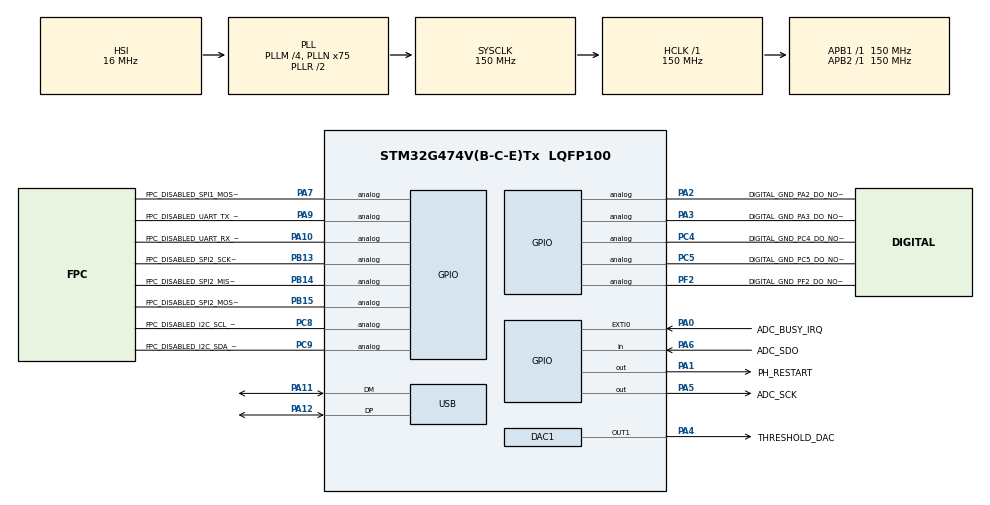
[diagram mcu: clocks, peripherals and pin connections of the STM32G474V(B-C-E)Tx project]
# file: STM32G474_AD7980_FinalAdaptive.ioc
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Mcu.Family=STM32G4
Mcu.Name=STM32G474V(B-C-E)Tx
Mcu.Package=LQFP100
NVIC.EXTI0_IRQn=true\:5\:0\:false\:false\:true\:true\:true\:true
NVIC.PriorityGroup=NVIC_PRIORITYGROUP_4
NVIC.USB_LP_IRQn=true\:6\:0\:true\:false\:true\:false\:true\:true
PA0.GPIO_Label=ADC_BUSY_IRQ
PA0.GPIO_ModeDefaultEXTI=GPIO_MODE_IT_FALLING
PA0.GPIO_PuPd=GPIO_NOPULL
PA0.Signal=GPXTI0
PA1.GPIO_Label=PH_RESTART
PA1.GPIO_PuPd=GPIO_NOPULL
PA1.GPIO_Speed=GPIO_SPEED_FREQ_HIGH
PA1.PinState=GPIO_PIN_RESET
PA1.Signal=GPIO_Output
PA2.GPIO_Label=DIGITAL_GND_PA2_DO_NOT_DRIVE
PA2.Signal=GPIO_Analog
PA3.GPIO_Label=DIGITAL_GND_PA3_DO_NOT_DRIVE
PA3.Signal=GPIO_Analog
PA11.Mode=Device
PA11.Signal=USB_DM
PA12.Mode=Device
PA12.Signal=USB_DP
PA4.GPIO_Label=THRESHOLD_DAC
PA4.Signal=COMP_DAC11_group
PA5.GPIO_Label=ADC_SCK
PA5.GPIO_PuPd=GPIO_NOPULL
PA5.GPIO_Speed=GPIO_SPEED_FREQ_VERY_HIGH
PA5.PinState=GPIO_PIN_RESET
PA5.Signal=GPIO_Output
PA6.GPIO_Label=ADC_SDO
PA6.GPIO_PuPd=GPIO_NOPULL
PA6.Signal=GPIO_Input
PA7.GPIO_Label=FPC_DISABLED_SPI1_MOSI_PA7
PA7.Signal=GPIO_Analog
PA9.GPIO_Label=FPC_DISABLED_UART_TX_PA9
PA9.Signal=GPIO_Analog
PA10.GPIO_Label=FPC_DISABLED_UART_RX_PA10
PA10.Signal=GPIO_Analog
PB13.GPIO_Label=FPC_DISABLED_SPI2_SCK_PB13
PB13.Signal=GPIO_Analog
PB14.GPIO_Label=FPC_DISABLED_SPI2_MISO_PB14
PB14.Signal=GPIO_Analog
PB15.GPIO_Label=FPC_DISABLED_SPI2_MOSI_PB15
PB15.Signal=GPIO_Analog
PC4.GPIO_Label=DIGITAL_GND_PC4_DO_NOT_DRIVE
PC4.Signal=GPIO_Analog
PC5.GPIO_Label=DIGITAL_GND_PC5_DO_NOT_DRIVE
PC5.Signal=GPIO_Analog
PC8.GPIO_Label=FPC_DISABLED_I2C_SCL_PC8
PC8.Signal=GPIO_Analog
PC9.GPIO_Label=FPC_DISABLED_I2C_SDA_PC9
PC9.Signal=GPIO_Analog
PF2.GPIO_Label=DIGITAL_GND_PF2_DO_NOT_DRIVE
PF2.Signal=GPIO_Analog
ProjectManager.HeapSize=0x800
ProjectManager.StackSize=0x1000
ProjectManager.TargetToolchain=STM32CubeIDE
RCC.ADC12Freq_Value=150000000
RCC.ADC345Freq_Value=150000000
RCC.AHBFreq_Value=150000000
RCC.APB1Freq_Value=150000000
RCC.APB1TimFreq_Value=150000000
RCC.APB2Freq_Value=150000000
RCC.APB2TimFreq_Value=150000000
RCC.CK48CLockSelection=RCC_USBCLKSOURCE_HSI48
RCC.CortexFreq_Value=150000000
RCC.EXTERNAL_CLOCK_VALUE=8000000
RCC.HCLKFreq_Value=150000000
RCC.HSE_VALUE=8000000
RCC.HSI48_VALUE=48000000
RCC.HSI_VALUE=16000000
RCC.LSE_VALUE=32768
RCC.PLLM=RCC_PLLM_DIV4
RCC.PLLN=75
RCC.SYSCLKFreq_VALUE=150000000
RCC.SYSCLKSource=RCC_SYSCLKSOURCE_PLLCLK
RCC.USBFreq_Value=48000000
RCC.VCOOutputFreq_Value=300000000
SH.COMP_DAC11_group.0=DAC1_OUT1,DAC_OUT1
USB.DeviceSpeed=PCD_SPEED_FULL
USB.Sof_enable=DISABLE
USB.battery_charging_enable=DISABLE
USB.low_power_enable=DISABLE
USB.lpm_enable=DISABLE
USB.phy_itface=PCD_PHY_EMBEDDED
USB_DEVICE.APP_RX_DATA_SIZE=512
USB_DEVICE.APP_TX_DATA_SIZE=512
USB_DEVICE.CLASS_NAME_FS=CDC
USB_DEVICE.CONFIGURATION_STRING_CDC_FS=AD7980 MCA CDC Config
USB_DEVICE.INTERFACE_STRING_CDC_FS=AD7980 MCA Data
USB_DEVICE.LANGID_STRING=2052
USB_DEVICE.MANUFACTURER_STRING=Nuclear Electronics Team
USB_DEVICE.PID_CDC_FS=0x5740
USB_DEVICE.PRODUCT_STRING_CDC_FS=STM32G474 AD7980 MCA
USB_DEVICE.USBD_DEBUG_LEVEL=0
USB_DEVICE.USBD_LPM_ENABLED=0
USB_DEVICE.USBD_MAX_NUM_CONFIGURATION=1
USB_DEVICE.USBD_MAX_NUM_INTERFACES=1
USB_DEVICE.USBD_MAX_STR_DESC_SIZ=100
USB_DEVICE.USBD_SELF_POWERED=1
USB_DEVICE.VID=0x0483
USB_DEVICE.VirtualMode=Cdc
USB_DEVICE.VirtualModeFS=Cdc_FS
VP_SYS_VS_DBSignals.Mode=DisableDeadBatterySignals
VP_USB_DEVICE_VS_USB_DEVICE_CDC_FS.Mode=CDC_FS
board=custom

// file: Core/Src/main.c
/* USER CODE BEGIN Header */
/**
  ******************************************************************************
  * @file           : main.c
  * @brief          : Main program body
  ******************************************************************************
  * @attention
  *
  * Copyright (c) 2026 STMicroelectronics.
  * All rights reserved.
  *
  * This software is licensed under terms that can be found in the LICENSE file
  * in the root directory of this software component.
  * If no LICENSE file comes with this software, it is provided AS-IS.
  *
  ******************************************************************************
  */
/* USER CODE END Header */
#include "main.h"
#include "usb_device.h"

/* USER CODE BEGIN Includes */
#include "ad7980.h"
#include "app.h"

/* USER CODE END Includes */

DAC_HandleTypeDef hdac1;

void SystemClock_Config(void);
static void MX_GPIO_Init(void);
static void MX_DAC1_Init(void);

int main(void)
{

  /* MCU Configuration--------------------------------------------------------*/

  /* Reset of all peripherals, Initializes the Flash interface and the Systick. */
  HAL_Init();

  /* Configure the system clock */
  SystemClock_Config();

  /* Initialize all configured peripherals */
  MX_GPIO_Init();
  MX_DAC1_Init();
  MX_USB_Device_Init();
  /* USER CODE BEGIN 2 */
  App_Init(&hdac1);
  /* Allow the 9.1k/1k + 100 nF threshold node to settle before enabling
   * the SDO/BUSY interrupt. CNV remains exclusively hardware generated. */
  HAL_Delay(2U);
  AD7980_Init();

  /* USER CODE END 2 */

  /* Infinite loop */
  /* USER CODE BEGIN WHILE */
  while (1)
  {
    App_Run();
    /* USER CODE END WHILE */

  }
}

void SystemClock_Config(void)
{
  RCC_OscInitTypeDef RCC_OscInitStruct = {0};
  RCC_ClkInitTypeDef RCC_ClkInitStruct = {0};

  /** Configure the main internal regulator output voltage
  */
  HAL_PWREx_ControlVoltageScaling(PWR_REGULATOR_VOLTAGE_SCALE1);

  /** Initializes the RCC Oscillators according to the specified parameters
  * in the RCC_OscInitTypeDef structure.
  */
  RCC_OscInitStruct.OscillatorType = RCC_OSCILLATORTYPE_HSI|RCC_OSCILLATORTYPE_HSI48;
  RCC_OscInitStruct.HSIState = RCC_HSI_ON;
  RCC_OscInitStruct.HSICalibrationValue = RCC_HSICALIBRATION_DEFAULT;
  RCC_OscInitStruct.HSI48State = RCC_HSI48_ON;
  RCC_OscInitStruct.PLL.PLLState = RCC_PLL_ON;
  RCC_OscInitStruct.PLL.PLLSource = RCC_PLLSOURCE_HSI;
  RCC_OscInitStruct.PLL.PLLM = RCC_PLLM_DIV4;
  RCC_OscInitStruct.PLL.PLLN = 75;
  RCC_OscInitStruct.PLL.PLLP = RCC_PLLP_DIV2;
  RCC_OscInitStruct.PLL.PLLQ = RCC_PLLQ_DIV2;
  RCC_OscInitStruct.PLL.PLLR = RCC_PLLR_DIV2;
  if (HAL_RCC_OscConfig(&RCC_OscInitStruct) != HAL_OK)
  {
    Error_Handler();
  }

  /** Initializes the CPU, AHB and APB buses clocks
  */
  RCC_ClkInitStruct.ClockType = RCC_CLOCKTYPE_HCLK|RCC_CLOCKTYPE_SYSCLK
                              |RCC_CLOCKTYPE_PCLK1|RCC_CLOCKTYPE_PCLK2;
  RCC_ClkInitStruct.SYSCLKSource = RCC_SYSCLKSOURCE_PLLCLK;
  RCC_ClkInitStruct.AHBCLKDivider = RCC_SYSCLK_DIV1;
  RCC_ClkInitStruct.APB1CLKDivider = RCC_HCLK_DIV1;
  RCC_ClkInitStruct.APB2CLKDivider = RCC_HCLK_DIV1;

  if (HAL_RCC_ClockConfig(&RCC_ClkInitStruct, FLASH_LATENCY_4) != HAL_OK)
  {
    Error_Handler();
  }
}

static void MX_DAC1_Init(void)
{

  DAC_ChannelConfTypeDef sConfig = {0};

  /** DAC Initialization
  */
  hdac1.Instance = DAC1;
  if (HAL_DAC_Init(&hdac1) != HAL_OK)
  {
    Error_Handler();
  }

  /** DAC channel OUT1 config
  */
  sConfig.DAC_HighFrequency = DAC_HIGH_FREQUENCY_INTERFACE_MODE_AUTOMATIC;
  sConfig.DAC_DMADoubleDataMode = DISABLE;
  sConfig.DAC_SignedFormat = DISABLE;
  sConfig.DAC_SampleAndHold = DAC_SAMPLEANDHOLD_DISABLE;
  sConfig.DAC_Trigger = DAC_TRIGGER_NONE;
  sConfig.DAC_Trigger2 = DAC_TRIGGER_NONE;
  sConfig.DAC_OutputBuffer = DAC_OUTPUTBUFFER_ENABLE;
  sConfig.DAC_ConnectOnChipPeripheral = DAC_CHIPCONNECT_EXTERNAL;
  sConfig.DAC_UserTrimming = DAC_TRIMMING_FACTORY;
  if (HAL_DAC_ConfigChannel(&hdac1, &sConfig, DAC_CHANNEL_1) != HAL_OK)
  {
    Error_Handler();
  }

}

static void MX_GPIO_Init(void)
{
  GPIO_InitTypeDef GPIO_InitStruct = {0};

  /* GPIO Ports Clock Enable */
  __HAL_RCC_GPIOF_CLK_ENABLE();
  __HAL_RCC_GPIOA_CLK_ENABLE();
  __HAL_RCC_GPIOB_CLK_ENABLE();
  __HAL_RCC_GPIOC_CLK_ENABLE();

  /*Configure GPIO pin Output Level */
  HAL_GPIO_WritePin(GPIOA, PH_RESTART_Pin|ADC_SCK_Pin, GPIO_PIN_RESET);

  /*Configure GPIO pin : DIGITAL_GND_PF2_DO_NOT_DRIVE_Pin */
  GPIO_InitStruct.Pin = DIGITAL_GND_PF2_DO_NOT_DRIVE_Pin;
  GPIO_InitStruct.Mode = GPIO_MODE_ANALOG;
  GPIO_InitStruct.Pull = GPIO_NOPULL;
  HAL_GPIO_Init(DIGITAL_GND_PF2_DO_NOT_DRIVE_GPIO_Port, &GPIO_InitStruct);

  /* PA2/PA3 are hard-grounded on the digital/power board.  Never use USART2. */
  GPIO_InitStruct.Pin = DIGITAL_GND_PA2_DO_NOT_DRIVE_Pin|DIGITAL_GND_PA3_DO_NOT_DRIVE_Pin;
  GPIO_InitStruct.Mode = GPIO_MODE_ANALOG;
  GPIO_InitStruct.Pull = GPIO_NOPULL;
  HAL_GPIO_Init(GPIOA, &GPIO_InitStruct);

  /*Configure GPIO pin : ADC_BUSY_IRQ_Pin */
  GPIO_InitStruct.Pin = ADC_BUSY_IRQ_Pin;
  GPIO_InitStruct.Mode = GPIO_MODE_IT_FALLING;
  GPIO_InitStruct.Pull = GPIO_NOPULL;
  HAL_GPIO_Init(ADC_BUSY_IRQ_GPIO_Port, &GPIO_InitStruct);

  /*Configure GPIO pin : PH_RESTART_Pin */
  GPIO_InitStruct.Pin = PH_RESTART_Pin;
  GPIO_InitStruct.Mode = GPIO_MODE_OUTPUT_PP;
  GPIO_InitStruct.Pull = GPIO_NOPULL;
  GPIO_InitStruct.Speed = GPIO_SPEED_FREQ_HIGH;
  HAL_GPIO_Init(PH_RESTART_GPIO_Port, &GPIO_InitStruct);

  /*Configure GPIO pin : ADC_SCK_Pin */
  GPIO_InitStruct.Pin = ADC_SCK_Pin;
  GPIO_InitStruct.Mode = GPIO_MODE_OUTPUT_PP;
  GPIO_InitStruct.Pull = GPIO_NOPULL;
  GPIO_InitStruct.Speed = GPIO_SPEED_FREQ_VERY_HIGH;
  HAL_GPIO_Init(ADC_SCK_GPIO_Port, &GPIO_InitStruct);

  /*Configure GPIO pin : ADC_SDO_Pin */
  GPIO_InitStruct.Pin = ADC_SDO_Pin;
  GPIO_InitStruct.Mode = GPIO_MODE_INPUT;
  GPIO_InitStruct.Pull = GPIO_NOPULL;
  HAL_GPIO_Init(ADC_SDO_GPIO_Port, &GPIO_InitStruct);

  /* PC4/PC5 are hard-grounded on the digital board: keep high-Z. */
  GPIO_InitStruct.Pin = DIGITAL_GND_PC4_DO_NOT_DRIVE_Pin|DIGITAL_GND_PC5_DO_NOT_DRIVE_Pin;
  GPIO_InitStruct.Mode = GPIO_MODE_ANALOG;
  GPIO_InitStruct.Pull = GPIO_NOPULL;
  HAL_GPIO_Init(DIGITAL_GND_PC4_DO_NOT_DRIVE_GPIO_Port, &GPIO_InitStruct);

  /* Unused FPC/LCD functions are explicitly analog/high-Z. */
  GPIO_InitStruct.Pin = FPC_DISABLED_SPI1_MOSI_PA7_Pin|
                        FPC_DISABLED_UART_TX_PA9_Pin|
                        FPC_DISABLED_UART_RX_PA10_Pin;
  HAL_GPIO_Init(GPIOA, &GPIO_InitStruct);

  GPIO_InitStruct.Pin = FPC_DISABLED_I2C_SCL_PC8_Pin|
                        FPC_DISABLED_I2C_SDA_PC9_Pin;
  HAL_GPIO_Init(GPIOC, &GPIO_InitStruct);

  GPIO_InitStruct.Pin = FPC_DISABLED_SPI2_SCK_PB13_Pin|
                        FPC_DISABLED_SPI2_MISO_PB14_Pin|
                        FPC_DISABLED_SPI2_MOSI_PB15_Pin;
  HAL_GPIO_Init(GPIOB, &GPIO_InitStruct);

  /* EXTI interrupt init*/
  HAL_NVIC_SetPriority(EXTI0_IRQn, 5, 0);
  /* Enabled by AD7980_Init only after DAC threshold settling. */

}

/* USER CODE BEGIN 4 */
void HAL_GPIO_EXTI_Callback(uint16_t GPIO_Pin)
{
  if (GPIO_Pin == ADC_BUSY_IRQ_Pin)
  {
    AD7980_BusyISR();
  }
}

/* USER CODE END 4 */

void Error_Handler(void)
{
  __disable_irq();
  while (1)
  {
  }
}
